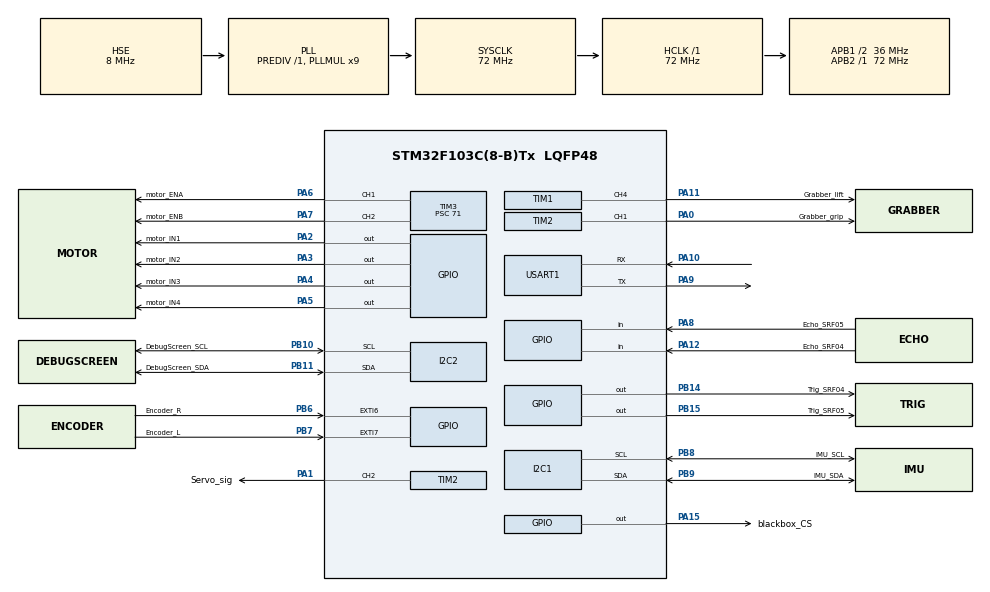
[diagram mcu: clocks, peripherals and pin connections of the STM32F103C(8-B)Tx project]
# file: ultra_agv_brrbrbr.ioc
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I2C1.I2C_Mode=I2C_Fast
I2C2.I2C_Mode=I2C_Standard
Mcu.Family=STM32F1
Mcu.Name=STM32F103C(8-B)Tx
Mcu.Package=LQFP48
NVIC.EXTI9_5_IRQn=true\:0\:0\:false\:false\:true\:true\:true\:true
NVIC.PriorityGroup=NVIC_PRIORITYGROUP_4
NVIC.TIM2_IRQn=true\:0\:0\:false\:false\:true\:true\:true\:true
NVIC.TIM3_IRQn=true\:0\:0\:false\:false\:true\:true\:true\:true
PA0-WKUP.GPIO_Label=Grabber_grip
PA0-WKUP.Signal=S_TIM2_CH1_ETR
PA1.GPIO_Label=Servo_sig
PA1.Signal=S_TIM2_CH2
PA10.Mode=Asynchronous
PA10.Signal=USART1_RX
PA11.GPIO_Label=Grabber_lift
PA11.Signal=S_TIM1_CH4
PA12.GPIO_Label=Echo_SRF04
PA12.GPIO_PuPd=GPIO_PULLDOWN
PA12.Signal=GPIO_Input
PA13.Mode=Serial_Wire
PA13.Signal=SYS_JTMS-SWDIO
PA14.Mode=Serial_Wire
PA14.Signal=SYS_JTCK-SWCLK
PA15.GPIO_Label=blackbox_CS
PA15.GPIO_ModeDefaultOutputPP=GPIO_MODE_OUTPUT_PP
PA15.GPIO_PuPd=GPIO_NOPULL
PA15.GPIO_Speed=GPIO_SPEED_FREQ_HIGH
PA15.PinState=GPIO_PIN_SET
PA15.Signal=GPIO_Output
PA2.GPIO_Label=motor_IN1
PA2.GPIO_Speed=GPIO_SPEED_FREQ_HIGH
PA2.PinState=GPIO_PIN_RESET
PA2.Signal=GPIO_Output
PA3.GPIO_Label=motor_IN2
PA3.GPIO_Speed=GPIO_SPEED_FREQ_HIGH
PA3.Signal=GPIO_Output
PA4.GPIO_Label=motor_IN3
PA4.GPIO_Speed=GPIO_SPEED_FREQ_HIGH
PA4.Signal=GPIO_Output
PA5.GPIO_Label=motor_IN4
PA5.GPIO_Speed=GPIO_SPEED_FREQ_HIGH
PA5.Signal=GPIO_Output
PA6.GPIO_Label=motor_ENA
PA6.Signal=S_TIM3_CH1
PA7.GPIO_Label=motor_ENB
PA7.Signal=S_TIM3_CH2
PA8.GPIO_Label=Echo_SRF05
PA8.GPIO_PuPd=GPIO_PULLDOWN
PA8.Signal=GPIO_Input
PA9.Mode=Asynchronous
PA9.Signal=USART1_TX
PB10.GPIO_Label=DebugScreen_SCL
PB10.Mode=I2C
PB10.Signal=I2C2_SCL
PB11.GPIO_Label=DebugScreen_SDA
PB11.Mode=I2C
PB11.Signal=I2C2_SDA
PB14.GPIO_Label=Trig_SRF04
PB14.Signal=GPIO_Output
PB15.GPIO_Label=Trig_SRF05
PB15.Signal=GPIO_Output
PB6.GPIO_Label=Encoder_R
PB6.GPIO_ModeDefaultEXTI=GPIO_MODE_IT_RISING_FALLING
PB6.GPIO_PuPd=GPIO_PULLUP
PB6.Signal=GPXTI6
PB7.GPIO_Label=Encoder_L
PB7.GPIO_ModeDefaultEXTI=GPIO_MODE_IT_RISING_FALLING
PB7.GPIO_PuPd=GPIO_PULLUP
PB7.Signal=GPXTI7
PB8.GPIO_Label=IMU_SCL
PB8.Mode=I2C
PB8.Signal=I2C1_SCL
PB9.GPIO_Label=IMU_SDA
PB9.Mode=I2C
PB9.Signal=I2C1_SDA
PD0-OSC_IN.Mode=HSE-External-Oscillator
PD0-OSC_IN.Signal=RCC_OSC_IN
PD1-OSC_OUT.Mode=HSE-External-Oscillator
PD1-OSC_OUT.Signal=RCC_OSC_OUT
ProjectManager.HeapSize=0x200
ProjectManager.StackSize=0x400
ProjectManager.TargetToolchain=CMake
RCC.AHBFreq_Value=72000000
RCC.APB1CLKDivider=RCC_HCLK_DIV2
RCC.APB1Freq_Value=36000000
RCC.APB1TimFreq_Value=72000000
RCC.APB2Freq_Value=72000000
RCC.APB2TimFreq_Value=72000000
RCC.HCLKFreq_Value=72000000
RCC.PLLMUL=RCC_PLL_MUL9
RCC.PLLSourceVirtual=RCC_PLLSOURCE_HSE
RCC.SYSCLKFreq_VALUE=72000000
RCC.SYSCLKSource=RCC_SYSCLKSOURCE_PLLCLK
RCC.USBFreq_Value=72000000
SH.S_TIM1_CH4.0=TIM1_CH4,PWM Generation4 CH4
SH.S_TIM2_CH1_ETR.0=TIM2_CH1,PWM Generation1 CH1
SH.S_TIM2_CH2.0=TIM2_CH2,PWM Generation2 CH2
SH.S_TIM3_CH1.0=TIM3_CH1,PWM Generation1 CH1
SH.S_TIM3_CH2.0=TIM3_CH2,PWM Generation2 CH2
TIM1.Channel-PWM\ Generation4\ CH4=TIM_CHANNEL_4
TIM1.Period=19999
TIM1.Prescaler=71
TIM2.Channel-PWM\ Generation1\ CH1=TIM_CHANNEL_1
TIM2.Channel-PWM\ Generation2\ CH2=TIM_CHANNEL_2
TIM2.Period=19999
TIM2.Prescaler=71
TIM3.Channel-PWM\ Generation1\ CH1=TIM_CHANNEL_1
TIM3.Channel-PWM\ Generation2\ CH2=TIM_CHANNEL_2
TIM3.Period=999
TIM3.Prescaler=71
USART1.VirtualMode=VM_ASYNC
VP_TIM1_VS_ClockSourceINT.Mode=Internal
VP_TIM2_VS_ClockSourceINT.Mode=Internal
VP_TIM3_VS_ClockSourceINT.Mode=Internal
board=custom

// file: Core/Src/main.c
/* USER CODE BEGIN Header */
/**
 ******************************************************************************
 * @file           : main.c
 * @brief          : Main program body
 ******************************************************************************
 * @attention
 *
 * Copyright (c) 2026 STMicroelectronics.
 * All rights reserved.
 *
 * This software is licensed under terms that can be found in the LICENSE file
 * in the root directory of this software component.
 * If no LICENSE file comes with this software, it is provided AS-IS.
 *
 ******************************************************************************
 */
/* USER CODE END Header */
#include "main.h"

/* USER CODE BEGIN Includes */
#include "agv.h"
#include "scanbench.h"
#include "motorbench.h"
#include "agvbench.h"

/* USER CODE END Includes */

I2C_HandleTypeDef hi2c1;
I2C_HandleTypeDef hi2c2;

TIM_HandleTypeDef htim1;
TIM_HandleTypeDef htim2;
TIM_HandleTypeDef htim3;

UART_HandleTypeDef huart1;

void SystemClock_Config(void);
static void MX_GPIO_Init(void);
static void MX_TIM2_Init(void);
static void MX_TIM3_Init(void);
static void MX_I2C2_Init(void);
static void MX_TIM1_Init(void);
static void MX_I2C1_Init(void);
static void MX_USART1_UART_Init(void);

int main(void)
{

  /* MCU Configuration--------------------------------------------------------*/

  /* Reset of all peripherals, Initializes the Flash interface and the Systick. */
  HAL_Init();

  /* Configure the system clock */
  SystemClock_Config();

  /* Initialize all configured peripherals */
  MX_GPIO_Init();
  MX_TIM2_Init();
  MX_TIM3_Init();
  MX_I2C2_Init();
  MX_TIM1_Init();
  MX_I2C1_Init();
  MX_USART1_UART_Init();
  /* USER CODE BEGIN 2 */
  agvInit();
  // agvTestScanGrabInit();

  /* USER CODE END 2 */

  /* Infinite loop */
  while (1)
  {

    /* USER CODE BEGIN 3 */
    agvRun();
    // scanBenchRun();
    // motorBenchRun();
    // agvBenchRun();
  }
  /* USER CODE END 3 */
}

void SystemClock_Config(void)
{
  RCC_OscInitTypeDef RCC_OscInitStruct = {0};
  RCC_ClkInitTypeDef RCC_ClkInitStruct = {0};

  /** Initializes the RCC Oscillators according to the specified parameters
  * in the RCC_OscInitTypeDef structure.
  */
  RCC_OscInitStruct.OscillatorType = RCC_OSCILLATORTYPE_HSE;
  RCC_OscInitStruct.HSEState = RCC_HSE_ON;
  RCC_OscInitStruct.HSEPredivValue = RCC_HSE_PREDIV_DIV1;
  RCC_OscInitStruct.HSIState = RCC_HSI_ON;
  RCC_OscInitStruct.PLL.PLLState = RCC_PLL_ON;
  RCC_OscInitStruct.PLL.PLLSource = RCC_PLLSOURCE_HSE;
  RCC_OscInitStruct.PLL.PLLMUL = RCC_PLL_MUL9;
  if (HAL_RCC_OscConfig(&RCC_OscInitStruct) != HAL_OK)
  {
    Error_Handler();
  }

  /** Initializes the CPU, AHB and APB buses clocks
  */
  RCC_ClkInitStruct.ClockType = RCC_CLOCKTYPE_HCLK|RCC_CLOCKTYPE_SYSCLK
                              |RCC_CLOCKTYPE_PCLK1|RCC_CLOCKTYPE_PCLK2;
  RCC_ClkInitStruct.SYSCLKSource = RCC_SYSCLKSOURCE_PLLCLK;
  RCC_ClkInitStruct.AHBCLKDivider = RCC_SYSCLK_DIV1;
  RCC_ClkInitStruct.APB1CLKDivider = RCC_HCLK_DIV2;
  RCC_ClkInitStruct.APB2CLKDivider = RCC_HCLK_DIV1;

  if (HAL_RCC_ClockConfig(&RCC_ClkInitStruct, FLASH_LATENCY_2) != HAL_OK)
  {
    Error_Handler();
  }
}

static void MX_I2C1_Init(void)
{

  hi2c1.Instance = I2C1;
  hi2c1.Init.ClockSpeed = 400000;
  hi2c1.Init.DutyCycle = I2C_DUTYCYCLE_2;
  hi2c1.Init.OwnAddress1 = 0;
  hi2c1.Init.AddressingMode = I2C_ADDRESSINGMODE_7BIT;
  hi2c1.Init.DualAddressMode = I2C_DUALADDRESS_DISABLE;
  hi2c1.Init.OwnAddress2 = 0;
  hi2c1.Init.GeneralCallMode = I2C_GENERALCALL_DISABLE;
  hi2c1.Init.NoStretchMode = I2C_NOSTRETCH_DISABLE;
  if (HAL_I2C_Init(&hi2c1) != HAL_OK)
  {
    Error_Handler();
  }

}

static void MX_I2C2_Init(void)
{

  hi2c2.Instance = I2C2;
  hi2c2.Init.ClockSpeed = 100000;
  hi2c2.Init.DutyCycle = I2C_DUTYCYCLE_2;
  hi2c2.Init.OwnAddress1 = 0;
  hi2c2.Init.AddressingMode = I2C_ADDRESSINGMODE_7BIT;
  hi2c2.Init.DualAddressMode = I2C_DUALADDRESS_DISABLE;
  hi2c2.Init.OwnAddress2 = 0;
  hi2c2.Init.GeneralCallMode = I2C_GENERALCALL_DISABLE;
  hi2c2.Init.NoStretchMode = I2C_NOSTRETCH_DISABLE;
  if (HAL_I2C_Init(&hi2c2) != HAL_OK)
  {
    Error_Handler();
  }

}

static void MX_TIM1_Init(void)
{

  TIM_ClockConfigTypeDef sClockSourceConfig = {0};
  TIM_MasterConfigTypeDef sMasterConfig = {0};
  TIM_OC_InitTypeDef sConfigOC = {0};
  TIM_BreakDeadTimeConfigTypeDef sBreakDeadTimeConfig = {0};

  htim1.Instance = TIM1;
  htim1.Init.Prescaler = 71;
  htim1.Init.CounterMode = TIM_COUNTERMODE_UP;
  htim1.Init.Period = 19999;
  htim1.Init.ClockDivision = TIM_CLOCKDIVISION_DIV1;
  htim1.Init.RepetitionCounter = 0;
  htim1.Init.AutoReloadPreload = TIM_AUTORELOAD_PRELOAD_DISABLE;
  if (HAL_TIM_Base_Init(&htim1) != HAL_OK)
  {
    Error_Handler();
  }
  sClockSourceConfig.ClockSource = TIM_CLOCKSOURCE_INTERNAL;
  if (HAL_TIM_ConfigClockSource(&htim1, &sClockSourceConfig) != HAL_OK)
  {
    Error_Handler();
  }
  if (HAL_TIM_PWM_Init(&htim1) != HAL_OK)
  {
    Error_Handler();
  }
  sMasterConfig.MasterOutputTrigger = TIM_TRGO_RESET;
  sMasterConfig.MasterSlaveMode = TIM_MASTERSLAVEMODE_DISABLE;
  if (HAL_TIMEx_MasterConfigSynchronization(&htim1, &sMasterConfig) != HAL_OK)
  {
    Error_Handler();
  }
  sConfigOC.OCMode = TIM_OCMODE_PWM1;
  sConfigOC.Pulse = 0;
  sConfigOC.OCPolarity = TIM_OCPOLARITY_HIGH;
  sConfigOC.OCFastMode = TIM_OCFAST_DISABLE;
  sConfigOC.OCIdleState = TIM_OCIDLESTATE_RESET;
  sConfigOC.OCNIdleState = TIM_OCNIDLESTATE_RESET;
  if (HAL_TIM_PWM_ConfigChannel(&htim1, &sConfigOC, TIM_CHANNEL_4) != HAL_OK)
  {
    Error_Handler();
  }
  sBreakDeadTimeConfig.OffStateRunMode = TIM_OSSR_DISABLE;
  sBreakDeadTimeConfig.OffStateIDLEMode = TIM_OSSI_DISABLE;
  sBreakDeadTimeConfig.LockLevel = TIM_LOCKLEVEL_OFF;
  sBreakDeadTimeConfig.DeadTime = 0;
  sBreakDeadTimeConfig.BreakState = TIM_BREAK_DISABLE;
  sBreakDeadTimeConfig.BreakPolarity = TIM_BREAKPOLARITY_HIGH;
  sBreakDeadTimeConfig.AutomaticOutput = TIM_AUTOMATICOUTPUT_DISABLE;
  if (HAL_TIMEx_ConfigBreakDeadTime(&htim1, &sBreakDeadTimeConfig) != HAL_OK)
  {
    Error_Handler();
  }
  HAL_TIM_MspPostInit(&htim1);

}

static void MX_TIM2_Init(void)
{

  TIM_ClockConfigTypeDef sClockSourceConfig = {0};
  TIM_MasterConfigTypeDef sMasterConfig = {0};
  TIM_OC_InitTypeDef sConfigOC = {0};

  htim2.Instance = TIM2;
  htim2.Init.Prescaler = 71;
  htim2.Init.CounterMode = TIM_COUNTERMODE_UP;
  htim2.Init.Period = 19999;
  htim2.Init.ClockDivision = TIM_CLOCKDIVISION_DIV1;
  htim2.Init.AutoReloadPreload = TIM_AUTORELOAD_PRELOAD_DISABLE;
  if (HAL_TIM_Base_Init(&htim2) != HAL_OK)
  {
    Error_Handler();
  }
  sClockSourceConfig.ClockSource = TIM_CLOCKSOURCE_INTERNAL;
  if (HAL_TIM_ConfigClockSource(&htim2, &sClockSourceConfig) != HAL_OK)
  {
    Error_Handler();
  }
  if (HAL_TIM_PWM_Init(&htim2) != HAL_OK)
  {
    Error_Handler();
  }
  sMasterConfig.MasterOutputTrigger = TIM_TRGO_RESET;
  sMasterConfig.MasterSlaveMode = TIM_MASTERSLAVEMODE_DISABLE;
  if (HAL_TIMEx_MasterConfigSynchronization(&htim2, &sMasterConfig) != HAL_OK)
  {
    Error_Handler();
  }
  sConfigOC.OCMode = TIM_OCMODE_PWM1;
  sConfigOC.Pulse = 0;
  sConfigOC.OCPolarity = TIM_OCPOLARITY_HIGH;
  sConfigOC.OCFastMode = TIM_OCFAST_DISABLE;
  if (HAL_TIM_PWM_ConfigChannel(&htim2, &sConfigOC, TIM_CHANNEL_1) != HAL_OK)
  {
    Error_Handler();
  }
  if (HAL_TIM_PWM_ConfigChannel(&htim2, &sConfigOC, TIM_CHANNEL_2) != HAL_OK)
  {
    Error_Handler();
  }
  HAL_TIM_MspPostInit(&htim2);

}

static void MX_TIM3_Init(void)
{

  TIM_ClockConfigTypeDef sClockSourceConfig = {0};
  TIM_MasterConfigTypeDef sMasterConfig = {0};
  TIM_OC_InitTypeDef sConfigOC = {0};

  htim3.Instance = TIM3;
  htim3.Init.Prescaler = 71;
  htim3.Init.CounterMode = TIM_COUNTERMODE_UP;
  htim3.Init.Period = 999;
  htim3.Init.ClockDivision = TIM_CLOCKDIVISION_DIV1;
  htim3.Init.AutoReloadPreload = TIM_AUTORELOAD_PRELOAD_DISABLE;
  if (HAL_TIM_Base_Init(&htim3) != HAL_OK)
  {
    Error_Handler();
  }
  sClockSourceConfig.ClockSource = TIM_CLOCKSOURCE_INTERNAL;
  if (HAL_TIM_ConfigClockSource(&htim3, &sClockSourceConfig) != HAL_OK)
  {
    Error_Handler();
  }
  if (HAL_TIM_PWM_Init(&htim3) != HAL_OK)
  {
    Error_Handler();
  }
  sMasterConfig.MasterOutputTrigger = TIM_TRGO_RESET;
  sMasterConfig.MasterSlaveMode = TIM_MASTERSLAVEMODE_DISABLE;
  if (HAL_TIMEx_MasterConfigSynchronization(&htim3, &sMasterConfig) != HAL_OK)
  {
    Error_Handler();
  }
  sConfigOC.OCMode = TIM_OCMODE_PWM1;
  sConfigOC.Pulse = 0;
  sConfigOC.OCPolarity = TIM_OCPOLARITY_HIGH;
  sConfigOC.OCFastMode = TIM_OCFAST_DISABLE;
  if (HAL_TIM_PWM_ConfigChannel(&htim3, &sConfigOC, TIM_CHANNEL_1) != HAL_OK)
  {
    Error_Handler();
  }
  if (HAL_TIM_PWM_ConfigChannel(&htim3, &sConfigOC, TIM_CHANNEL_2) != HAL_OK)
  {
    Error_Handler();
  }
  HAL_TIM_MspPostInit(&htim3);

}

static void MX_USART1_UART_Init(void)
{

  huart1.Instance = USART1;
  huart1.Init.BaudRate = 115200;
  huart1.Init.WordLength = UART_WORDLENGTH_8B;
  huart1.Init.StopBits = UART_STOPBITS_1;
  huart1.Init.Parity = UART_PARITY_NONE;
  huart1.Init.Mode = UART_MODE_TX_RX;
  huart1.Init.HwFlowCtl = UART_HWCONTROL_NONE;
  huart1.Init.OverSampling = UART_OVERSAMPLING_16;
  if (HAL_UART_Init(&huart1) != HAL_OK)
  {
    Error_Handler();
  }

}

static void MX_GPIO_Init(void)
{
  GPIO_InitTypeDef GPIO_InitStruct = {0};

  /* GPIO Ports Clock Enable */
  __HAL_RCC_GPIOD_CLK_ENABLE();
  __HAL_RCC_GPIOA_CLK_ENABLE();
  __HAL_RCC_GPIOB_CLK_ENABLE();

  /*Configure GPIO pin Output Level */
  HAL_GPIO_WritePin(GPIOA, motor_IN1_Pin|motor_IN2_Pin|motor_IN3_Pin|motor_IN4_Pin, GPIO_PIN_RESET);

  /*Configure GPIO pin Output Level */
  HAL_GPIO_WritePin(GPIOB, Trig_SRF04_Pin|Trig_SRF05_Pin, GPIO_PIN_RESET);

  /*Configure GPIO pin Output Level */
  HAL_GPIO_WritePin(blackbox_CS_GPIO_Port, blackbox_CS_Pin, GPIO_PIN_SET);

  /*Configure GPIO pins : motor_IN1_Pin motor_IN2_Pin motor_IN3_Pin motor_IN4_Pin
                           blackbox_CS_Pin */
  GPIO_InitStruct.Pin = motor_IN1_Pin|motor_IN2_Pin|motor_IN3_Pin|motor_IN4_Pin
                          |blackbox_CS_Pin;
  GPIO_InitStruct.Mode = GPIO_MODE_OUTPUT_PP;
  GPIO_InitStruct.Pull = GPIO_NOPULL;
  GPIO_InitStruct.Speed = GPIO_SPEED_FREQ_HIGH;
  HAL_GPIO_Init(GPIOA, &GPIO_InitStruct);

  /*Configure GPIO pins : Trig_SRF04_Pin Trig_SRF05_Pin */
  GPIO_InitStruct.Pin = Trig_SRF04_Pin|Trig_SRF05_Pin;
  GPIO_InitStruct.Mode = GPIO_MODE_OUTPUT_PP;
  GPIO_InitStruct.Pull = GPIO_NOPULL;
  GPIO_InitStruct.Speed = GPIO_SPEED_FREQ_LOW;
  HAL_GPIO_Init(GPIOB, &GPIO_InitStruct);

  /*Configure GPIO pins : Echo_SRF05_Pin Echo_SRF04_Pin */
  GPIO_InitStruct.Pin = Echo_SRF05_Pin|Echo_SRF04_Pin;
  GPIO_InitStruct.Mode = GPIO_MODE_INPUT;
  GPIO_InitStruct.Pull = GPIO_PULLDOWN;
  HAL_GPIO_Init(GPIOA, &GPIO_InitStruct);

  /*Configure GPIO pins : Encoder_R_Pin Encoder_L_Pin */
  GPIO_InitStruct.Pin = Encoder_R_Pin|Encoder_L_Pin;
  GPIO_InitStruct.Mode = GPIO_MODE_IT_RISING_FALLING;
  GPIO_InitStruct.Pull = GPIO_PULLUP;
  HAL_GPIO_Init(GPIOB, &GPIO_InitStruct);

  /* EXTI interrupt init*/
  HAL_NVIC_SetPriority(EXTI9_5_IRQn, 0, 0);
  HAL_NVIC_EnableIRQ(EXTI9_5_IRQn);

}

void Error_Handler(void)
{
  __disable_irq();
  while (1)
  {
  }
}
